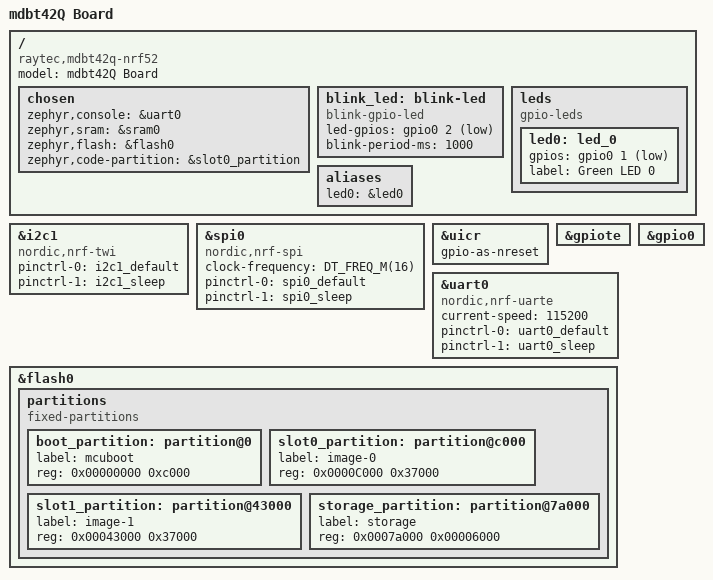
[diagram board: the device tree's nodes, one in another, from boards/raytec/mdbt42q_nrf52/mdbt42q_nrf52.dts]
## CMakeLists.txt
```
#
# Copyright (c) 2016 Intel Corporation
#
# SPDX-License-Identifier: Apache-2.0
#


add_subdirectory(drivers)

zephyr_syscall_include_directories(include)
zephyr_include_directories(include)
```

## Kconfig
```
# mainmenu "lvgl_nrf52840_mdk_sample"
# source "Kconfig.zephyr"

# Copyright (c) 2021 Nordic Semiconductor ASA
# SPDX-License-Identifier: Apache-2.0
#
# This Kconfig file is picked by the Zephyr build system because it is defined
# as the module Kconfig entry point (see zephyr/module.yml). You can browse
# module options by going to Zephyr -> Modules in Kconfig.

rsource "drivers/Kconfig"
```

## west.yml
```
# Copyright (c) 2021 Nordic Semiconductor ASA
# SPDX-License-Identifier: Apache-2.0

manifest:
  self:
    path: hud-nordic
    west-commands: scripts/west-commands.yml

  remotes:
    - name: zephyrproject-rtos
      url-base: https://github.com/zephyrproject-rtos

  projects:
    - name: zephyr
      remote: zephyrproject-rtos
      revision: main
      import:
        # By using name-allowlist we can clone only the modules that are
        # strictly needed by the application.
        name-allowlist:
          - cmsis
          - hal_nordic
          - segger
          #- tinycrypt
          - lvgl
```

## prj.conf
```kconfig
CONFIG_GPIO=y
CONFIG_CLOCK_CONTROL_NRF_K32SRC_RC=y

CONFIG_DEBUG=y

CONFIG_MAIN_STACK_SIZE=2048
CONFIG_SYSTEM_WORKQUEUE_STACK_SIZE=2048

#CONFIG_HEAP_MEM_POOL_SIZE=12288
#CONFIG_LV_Z_MEM_POOL_SIZE=8192

# Hardware config
CONFIG_GPIO=y

# Hardware config
CONFIG_SPI=y
CONFIG_SPI_SLAVE=n
#CONFIG_NRFX_SPIM = y
CONFIG_SOC_NRF52832_ALLOW_SPIM_DESPITE_PAN_58=y
CONFIG_SPI_NRFX=y
CONFIG_SPI_NRFX_RAM_BUFFER_SIZE=32

CONFIG_I2C=y
CONFIG_SENSOR=y

CONFIG_ST7735R=y
CONFIG_DISPLAY=y

#ONFIG_APP_LINK_WITH_LVGL=y

CONFIG_LV_CONF_MINIMAL=y
CONFIG_LVGL=y
#CONFIG_LV_MEM_CUSTOM=y
CONFIG_LV_USE_LOG=y
CONFIG_LV_USE_LABEL=y
# CONFIG_LV_USE_BTN=y
# CONFIG_LV_USE_IMG=y
CONFIG_LV_FONT_MONTSERRAT_24=y
CONFIG_LV_FONT_DEFAULT_MONTSERRAT_24=y
```

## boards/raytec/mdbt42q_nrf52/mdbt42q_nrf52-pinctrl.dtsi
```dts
/*
 * Copyright (c) 2022 Nordic Semiconductor ASA
 * SPDX-License-Identifier: Apache-2.0
 */

&pinctrl {
	uart0_default: uart0_default {
		group1 {
			psels = <NRF_PSEL(UART_TX, 0, 6)>,
				<NRF_PSEL(UART_RX, 0, 8)>,
				<NRF_PSEL(UART_RTS, 0, 5)>,
				<NRF_PSEL(UART_CTS, 0, 7)>;
		};
	};

	uart0_sleep: uart0_sleep {
		group1 {
			psels = <NRF_PSEL(UART_TX, 0, 6)>,
				<NRF_PSEL(UART_RX, 0, 8)>,
				<NRF_PSEL(UART_RTS, 0, 5)>,
				<NRF_PSEL(UART_CTS, 0, 7)>;
			low-power-enable;
		};
	};

	spi0_default: spi0_default {
		group1 {
			psels = <NRF_PSEL(SPIM_SCK, 0, 27)>,
				<NRF_PSEL(SPIM_MOSI, 0, 26)>,
				<NRF_PSEL(SPIM_MISO, 0, 28)>;
		};
	};

	spi0_sleep: spi0_sleep {
		group1 {
			psels = <NRF_PSEL(SPIM_SCK, 0, 27)>,
				<NRF_PSEL(SPIM_MOSI, 0, 26)>,
				<NRF_PSEL(SPIM_MISO, 0, 28)>;
			low-power-enable;
		};
	};

	i2c1_default: i2c1_default {
		group1 {
			psels = <NRF_PSEL(TWIM_SDA, 0, 30)>,
				<NRF_PSEL(TWIM_SCL, 0, 31)>;
		};
	};

	i2c1_sleep: i2c1_sleep {
		group1 {
			psels = <NRF_PSEL(TWIM_SDA, 0, 30)>,
				<NRF_PSEL(TWIM_SCL, 0, 31)>;
			low-power-enable;
		};
	};

};
```

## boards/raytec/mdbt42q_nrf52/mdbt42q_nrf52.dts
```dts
/*
 * Copyright (c) 2021 Nordic Semiconductor ASA
 * SPDX-License-Identifier: Apache-2.0
 */

/dts-v1/;
#include <nordic/nrf52832_qfaa.dtsi>
#include "mdbt42q_nrf52-pinctrl.dtsi"
#include <zephyr/dt-bindings/input/input-event-codes.h>

/ {
	model = "mdbt42Q Board";
	compatible = "raytec,mdbt42q-nrf52";

	chosen {
		zephyr,console = &uart0;
		// zephyr,sram = &sram0;
		// zephyr,flash = &flash0;
		zephyr,sram = &sram0;
		zephyr,flash = &flash0;
		zephyr,code-partition = &slot0_partition;
	};


	blink_led: blink-led {
		compatible = "blink-gpio-led";
		led-gpios = <&gpio0 2 GPIO_ACTIVE_LOW>;
		blink-period-ms = <1000>;
	};

	leds {
		compatible = "gpio-leds";
		led0: led_0 {
			gpios = <&gpio0 1 GPIO_ACTIVE_LOW>;
			label = "Green LED 0";
		};
	};

	// arduino_header: connector {
	// 	compatible = "arduino-header-r3";
	// 	#gpio-cells = <2>;
	// 	gpio-map-mask = <0xffffffff 0xffffffc0>;
	// 	gpio-map-pass-thru = <0 0x3f>;
	// 	gpio-map = <0 0 &gpio0 3 0>,	/* A0 */
	// 		   <1 0 &gpio0 4 0>,	/* A1 */
	// 		   <2 0 &gpio0 28 0>,	/* A2 */
	// 		   <3 0 &gpio0 29 0>,	/* A3 */
	// 		   <4 0 &gpio0 30 0>,	/* A4 */
	// 		   <5 0 &gpio0 31 0>,	/* A5 */
	// 		   <6 0 &gpio0 11 0>,	/* D0 */
	// 		   <7 0 &gpio0 12 0>,	/* D1 */
	// 		   <8 0 &gpio0 13 0>,	/* D2 */
	// 		   <9 0 &gpio0 14 0>,	/* D3 */
	// 		   <10 0 &gpio0 15 0>,	/* D4 */
	// 		   <11 0 &gpio0 16 0>,	/* D5 */
	// 		   <12 0 &gpio0 17 0>,	/* D6 */
	// 		   <13 0 &gpio0 18 0>,	/* D7 */
	// 		   <14 0 &gpio0 19 0>,	/* D8 */
	// 		   <15 0 &gpio0 20 0>,	/* D9 */
	// 		   <16 0 &gpio0 22 0>,	/* D10 */
	// 		   <17 0 &gpio0 23 0>,	/* D11 */
	// 		   <18 0 &gpio0 24 0>,	/* D12 */
	// 		   <19 0 &gpio0 25 0>,	/* D13 */
	// 		   <20 0 &gpio0 26 0>,	/* D14 */
	// 		   <21 0 &gpio0 27 0>;	/* D15 */
	// };

	aliases {
		led0 = &led0;
	};

};

arduino_i2c: &i2c1 {
	compatible = "nordic,nrf-twi";
	status = "okay";
	pinctrl-0 = <&i2c1_default>;
	pinctrl-1 = <&i2c1_sleep>;
	pinctrl-names = "default", "sleep";
};

arduino_spi: &spi0 {
	compatible = "nordic,nrf-spi";
	/* Cannot be used together with i2c0. */
	status = "okay";
	/* default freq 3M */
	clock-frequency = <DT_FREQ_M(16)>;
	pinctrl-0 = <&spi0_default>;
	pinctrl-1 = <&spi0_sleep>;
	pinctrl-names = "default", "sleep";
};

&uicr {
	gpio-as-nreset;
};

&gpiote {
	status = "okay";
};

&gpio0 {
	status = "okay";
};

&uart0 {
	compatible = "nordic,nrf-uarte";
	status = "okay";

	current-speed = <115200>;
	pinctrl-0 = <&uart0_default>;
	pinctrl-1 = <&uart0_sleep>;
	pinctrl-names = "default", "sleep";
};

&flash0 {

	partitions {
		compatible = "fixed-partitions";
		#address-cells = <1>;
		#size-cells = <1>;

		boot_partition: partition@0 {
			label = "mcuboot";
			reg = <0x00000000 0xc000>;
		};
		slot0_partition: partition@c000 {
			label = "image-0";
			reg = <0x0000C000 0x37000>;
		};
		slot1_partition: partition@43000 {
			label = "image-1";
			reg = <0x00043000 0x37000>;
		};
		storage_partition: partition@7a000 {
			label = "storage";
			reg = <0x0007a000 0x00006000>;
		};
	};
};

// &flash0 {

// 	partitions {
// 		compatible = "fixed-partitions";
// 		#address-cells = <1>;
// 		#size-cells = <1>;

// 		boot_partition: partition@0 {
// 			label = "mcuboot";
// 			reg = <0x0 0xc000>;
// 		};
// 		slot0_partition: partition@c000 {
// 			label = "image-0";
// 			reg = <0xc000 0x32000>;
// 		};
// 		slot1_partition: partition@3e000 {
// 			label = "image-1";
// 			reg = <0x3e000 0x32000>;
// 		};
// 		scratch_partition: partition@70000 {
// 			label = "image-scratch";
// 			reg = <0x70000 0xa000>;
// 		};
// 		storage_partition: partition@7a000 {
// 			label = "storage";
// 			reg = <0x7a000 0x6000>;
// 		};
// 	};
// };
```

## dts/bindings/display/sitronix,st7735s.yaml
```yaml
# Copyright (c) 2020, Kim Bøndergaard <kim@fam-boendergaard.dk>
# SPDX-License-Identifier: Apache-2.0

description: ST7735S 160x128 display controller

compatible: "sitronix,st7735s"

include: [spi-device.yaml, display-controller.yaml]

properties:
  reset-gpios:
    type: phandle-array
    description: RESET pin.

      The RESET pin of ST7735S is active low.
      If connected directly the MCU pin should be configured
      as active low.

  cmd-data-gpios:
    type: phandle-array
    required: true
    description: D/CX pin.

      The D/CX pin of ST7735S is active low (transmission command byte).
      If connected directly the MCU pin should be configured
      as active low.

  x-offset:
    type: int
    required: true
    description: The column offset in pixels of the LCD to the controller memory

  y-offset:
    type: int
    required: true
    description: The row offset in pixels of the LCD to the controller memory

  madctl:
    type: int
    default: 0x00
    description: Memory Data Access Control

  colmod:
    type: int
    default: 0x06
    description: Interface Pixel Format

  pwctr1:
    type: uint8-array
    default: [0xb4, 0x14, 0x04]
    description: Power Control 1 Parameter

  pwctr2:
    type: uint8-array
    default: [0xc0]
    description: Power Control 2 Parameter

  pwctr3:
    type: uint8-array
    default: [0x0a, 0x00]
    description: Power Control 3 Parameter

  pwctr4:
    type: uint8-array
    default: [0x8a, 0x26]
    description: Power Control 4 Parameter

  pwctr5:
    type: uint8-array
    default: [0x8a, 0xee]
    description: Power Control 5 Parameter

  gamctrp1:
    type: uint8-array
    required: true
    description: Positive Voltage Gamma Control Parameter

  gamctrn1:
    type: uint8-array
    required: true
    description: Negative Voltage Gamma Control Parameter

  frmctr1:
    type: uint8-array
    default: [0x05, 0x3a, 0x3a]
    description: Frame rate control (normal mode / full colors)

  frmctr2:
    type: uint8-array
    default: [0x05, 0x3a, 0x3a]
    description: Frame rate control (idle mode / 8 colors)

  frmctr3:
    type: uint8-array
    default: [0x05, 0x3a, 0x3a, 0x05, 0x3a, 0x3a]
    description: Frame rate control (partial mode / full colors)

  caset:
    type: uint8-array
    default: [0x00, 0x00, 0x00, 0x7f]
    description: Column Address Set

  raset:
    type: uint8-array
    default: [0x00, 0x00, 0x00, 0x9f]
    description: Row Address Set

  vmctr1:
    type: int
    default: 0x0a
    description: VCOM Control 1

  invctr:
    type: int
    default: 0x07
    description: |
      Display Inversion Control
      Set dot inversion or line inversion for each normal/idle/partial mode.

  inversion-on:
    type: boolean
    description: |
      Enable Display Inversion
      Make a drawing with the inverted color of the frame memory.

  rgb-is-inverted:
    type: boolean
    description: |
      Inverting color format order (RGB->BGR or BGR->RGB)
      In the case of enabling this option, API reports pixel-format in capabilities
      as the inverted value of the RGB pixel-format specified in MADCTL.
      This option is convenient for supporting displays with bugs
      where the actual color is different from the pixel format of MADCTL.
```

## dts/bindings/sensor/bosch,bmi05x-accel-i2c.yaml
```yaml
# Copyright (c) 2022 Meta Platforms, Inc. and its affiliates.
# SPDX-License-Identifier: Apache-2.0

description: BMI05X Accel inertial measurement unit

compatible: "bosch,bmi05x-accel"

include: [i2c-device.yaml, "bosch,bmi05x-accel.yaml"]
```

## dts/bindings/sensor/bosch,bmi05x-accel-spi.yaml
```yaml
# Copyright (c) 2022 Meta Platforms, Inc. and its affiliates.
# SPDX-License-Identifier: Apache-2.0

description: BMI05X Accel inertial measurement unit

compatible: "bosch,bmi05x-accel"

include: [spi-device.yaml, "bosch,bmi05x-accel.yaml"]
```

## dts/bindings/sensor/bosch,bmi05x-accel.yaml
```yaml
# Copyright (c) 2022 Meta Platforms, Inc. and its affiliates.
# SPDX-License-Identifier: Apache-2.0

description: BMI05X Accel inertial measurement unit

include: sensor-device.yaml

properties:
  int-gpios:
    type: phandle-array
    description: |
      This property specifies the connection for INT, because the
      Zephyr driver maps all interrupts to INT.  The signal defaults
      to output low when produced by the sensor.

  int1-map-io:
    type: int
    description: |
      Bit[0]: Map Interrupt A to INT1, Accel Data Ready
      Bit[1]: Map Interrupt B to INT1
      Bit[2]: Map Interrupt C to INT1

  int2-map-io:
    type: int
    description: |
      Bit[0]: Map Interrupt A to INT2, Accel Data Ready
      Bit[1]: Map Interrupt B to INT2
      Bit[2]: Map Interrupt C to INT2

  int1-conf-io:
    type: int
    description: |
      Bit[0]: reserved
      Bit[1]: if set to 1, INT1 is active high, otherwise it's active low
      Bit[2]: if set to 1, INT1 is open-drain, otherwise it's push-pull
      Bit[3]: if set to 1, enable INT1 as an output pin
      Bit[4]: if set to 1, enable INT1 as an input pin
      Bit[7:5] : reserved

  int2-conf-io:
    type: int
    description: |
      Bit[0]: reserved
      Bit[1]: if set to 1, INT2 is active high, otherwise it's active low
      Bit[2]: if set to 1, INT2 is open-drain, otherwise it's push-pull
      Bit[3]: if set to 1, enable INT2 as an output pin
      Bit[4]: if set to 1, enable INT2 as an input pin
      Bit[7:5] : reserved

  accel-hz:
    type: string
    required: true
    description: |
      Default frequency of accelerometer. (Unit - Hz)
    enum:
      - "12.5"
      - "25"
      - "50"
      - "100"
      - "200"
      - "400"
      - "800"
      - "1600"

  accel-fs:
    type: int
    required: true
    description: |
      Default full scale of accelerometer. (Unit - g)
    enum:
      - 2
      - 3
      - 4
      - 6
      - 8
      - 12
      - 16
      - 24

  data-sync:
    type: phandle
    description: |
      Enables data sync if defined. This is to point to the bmi05x-gyro definition
      that is within the same IC as the bmi05x-accel.
```

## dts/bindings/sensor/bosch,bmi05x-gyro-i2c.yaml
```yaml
# Copyright (c) 2022 Meta Platforms, Inc. and its affiliates.
# SPDX-License-Identifier: Apache-2.0

description: BMI05X Gyro inertial measurement unit

compatible: "bosch,bmi05x-gyro"

include: [i2c-device.yaml, "bosch,bmi05x-gyro.yaml"]
```

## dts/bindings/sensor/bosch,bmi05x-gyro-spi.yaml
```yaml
# Copyright (c) 2022 Meta Platforms, Inc. and its affiliates.
# SPDX-License-Identifier: Apache-2.0

description: BMI05X Gyro inertial measurement unit

compatible: "bosch,bmi05x-gyro"

include: [spi-device.yaml, "bosch,bmi05x-gyro.yaml"]
```

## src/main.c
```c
/*
 * Copyright (c) 2016 Intel Corporation
 *
 * SPDX-License-Identifier: Apache-2.0
 * Note: 
 * Tested on nRF Connect SDK Version : 2.0
 */

#include <zephyr/kernel.h>
#include <zephyr/device.h>
#include <zephyr/devicetree.h>

#include <zephyr/logging/log.h>

#include "control.h"
//#include "oled.h"

//LOG_MODULE_REGISTER(main, 3);

#define STACKSIZE 1024
#define PRIORITY 7


#define SLEEP_TIME_MS   10*60*1000




void main(void)
{
	int ret;
	//printk("hello");
	control_init();
	while (1) {

        k_msleep(SLEEP_TIME_MS);
	}
}
```

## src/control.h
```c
/*
 *   control.h
 */
#ifndef __CONTROL_H
#define __CONTROL_H

/*---------------------------------------------------------------------------*/
/*                                                                           */
/*---------------------------------------------------------------------------*/
int  control_init(void);

#endif  /* __CONTROL_H */
```

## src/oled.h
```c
/*
 *   display.h
 */
#ifndef __OLED_H
#define __OLED_H

/*---------------------------------------------------------------------------*/
/*                                                                           */
/*---------------------------------------------------------------------------*/
int  display_init(void);

#endif  /* __DISPLAY_H */
```
